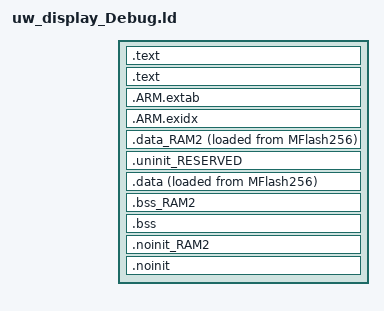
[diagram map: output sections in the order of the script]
/*
 * GENERATED FILE - DO NOT EDIT
 * (c) Code Red Technologies Ltd, 2008-13
 * (c) NXP Semiconductors 2013-2016
 * Generated linker script file for LPC1785
 * Created from generic_c.ld (7.7.2 ())
 * By LPCXpresso v7.7.2 [Build 379] [2015-03-31]  on Mon Sep 12 14:29:28 EEST 2016
 */


INCLUDE "uw_display_Debug_lib.ld"
INCLUDE "uw_display_Debug_mem.ld"

ENTRY(ResetISR)

SECTIONS
{

    /* MAIN TEXT SECTION */    
    .text : ALIGN(4)
    {
        FILL(0xff)
        __vectors_start__ = ABSOLUTE(.) ;
        KEEP(*(.isr_vector))
        
        /* Global Section Table */
        . = ALIGN(4) ;
        __section_table_start = .;
        __data_section_table = .;
        LONG(LOADADDR(.data));
        LONG(    ADDR(.data));
        LONG(  SIZEOF(.data));
        LONG(LOADADDR(.data_RAM2));
        LONG(    ADDR(.data_RAM2));
        LONG(  SIZEOF(.data_RAM2));
        __data_section_table_end = .;
        __bss_section_table = .;
        LONG(    ADDR(.bss));
        LONG(  SIZEOF(.bss));
        LONG(    ADDR(.bss_RAM2));
        LONG(  SIZEOF(.bss_RAM2));
        __bss_section_table_end = .;
        __section_table_end = . ;
        /* End of Global Section Table */
        

        *(.after_vectors*)
        
        /* Code Read Protect data */
        . = 0x000002FC ;
        PROVIDE(__CRP_WORD_START__ = .) ;
        KEEP(*(.crp))
        PROVIDE(__CRP_WORD_END__ = .) ;
        ASSERT(!(__CRP_WORD_START__ == __CRP_WORD_END__), "Linker CRP Enabled, but no CRP_WORD provided within application");
        /* End of Code Read Protect */
        
    } >MFlash256
    
    .text : ALIGN(4)    
    {
         *(.text*)
        *(.rodata .rodata.* .constdata .constdata.*)
        . = ALIGN(4);
        
    } > MFlash256

    /*
     * for exception handling/unwind - some Newlib functions (in common
     * with C++ and STDC++) use this. 
     */
    .ARM.extab : ALIGN(4)
    {
    	*(.ARM.extab* .gnu.linkonce.armextab.*)
    } > MFlash256
    __exidx_start = .;
    
    .ARM.exidx : ALIGN(4)
    {
    	*(.ARM.exidx* .gnu.linkonce.armexidx.*)
    } > MFlash256
    __exidx_end = .;
    
    _etext = .;
        
    
    /* DATA section for RamPeriph16 */
    .data_RAM2 : ALIGN(4)
    {
       FILL(0xff)
       PROVIDE(__start_data_RAM2 = .) ;
       *(.ramfunc.$RAM2)
       *(.ramfunc.$RamPeriph16)
    	*(.data.$RAM2*)
    	*(.data.$RamPeriph16*)
       . = ALIGN(4) ;
       PROVIDE(__end_data_RAM2 = .) ;
    } > RamPeriph16 AT>MFlash256
    
    /* MAIN DATA SECTION */
    

    .uninit_RESERVED : ALIGN(4)
    {
        KEEP(*(.bss.$RESERVED*))
        . = ALIGN(4) ;
        _end_uninit_RESERVED = .;
    } > RamLoc64

	
	/* Main DATA section (RamLoc64) */
	.data : ALIGN(4)
	{
	   FILL(0xff)
	   _data = . ;
	   *(vtable)
	   *(.ramfunc*)
	   *(.data*)
	   . = ALIGN(4) ;
	   _edata = . ;
	} > RamLoc64 AT>MFlash256

    /* BSS section for RamPeriph16 */
    .bss_RAM2 : ALIGN(4)
    {
       PROVIDE(__start_bss_RAM2 = .) ;
    	*(.bss.$RAM2*)
    	*(.bss.$RamPeriph16*)
       . = ALIGN(4) ;
       PROVIDE(__end_bss_RAM2 = .) ;
    } > RamPeriph16

    /* MAIN BSS SECTION */
    .bss : ALIGN(4)
    {
        _bss = .;
        *(.bss*)
        *(COMMON)
        . = ALIGN(4) ;
        _ebss = .;
        PROVIDE(end = .);
    } > RamLoc64
        
    /* NOINIT section for RamPeriph16 */
    .noinit_RAM2 (NOLOAD) : ALIGN(4)
    {
    	*(.noinit.$RAM2*)
    	*(.noinit.$RamPeriph16*)
       . = ALIGN(4) ;
    } > RamPeriph16 
    
    /* DEFAULT NOINIT SECTION */
    .noinit (NOLOAD): ALIGN(4)
    {
        _noinit = .;
        *(.noinit*) 
         . = ALIGN(4) ;
        _end_noinit = .;
    } > RamLoc64
    
    PROVIDE(_pvHeapStart = DEFINED(__user_heap_base) ? __user_heap_base : .);
    PROVIDE(_vStackTop = DEFINED(__user_stack_top) ? __user_stack_top : __top_RamLoc64 - 0);
}
